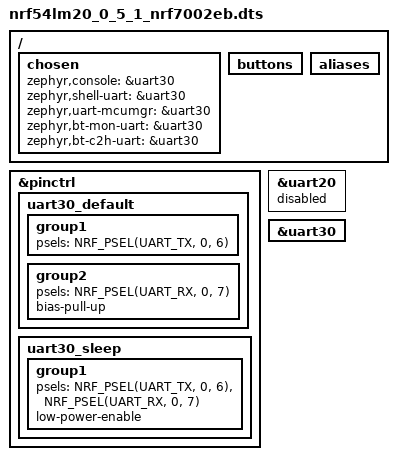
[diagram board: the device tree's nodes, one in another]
/*
 * nRF7002 EB-II SoC overlay for nRF54LM20 revision 0.5.1.
 * SPI and GPIOs come from root overlay via nordic_expansion_spi and
 * nordic_expansion_header.
 */

/* UART20 conflicts with EB-II shield on 0.5.1 board revision; use UART30 */
/ {
	chosen {
		zephyr,console = &uart30;
		zephyr,shell-uart = &uart30;
		zephyr,uart-mcumgr = &uart30;
		zephyr,bt-mon-uart = &uart30;
		zephyr,bt-c2h-uart = &uart30;
	};

	buttons {
		/delete-node/ button_3;
	};

	aliases {
		/delete-property/ sw3;
	};
};

&pinctrl {
	uart30_default: uart30_default {
		group1 {
			psels = <NRF_PSEL(UART_TX, 0, 6)>;
		};

		group2 {
			psels = <NRF_PSEL(UART_RX, 0, 7)>;
			bias-pull-up;
		};
	};

	uart30_sleep: uart30_sleep {
		group1 {
			psels = <NRF_PSEL(UART_TX, 0, 6)>,
				<NRF_PSEL(UART_RX, 0, 7)>;
			low-power-enable;
		};
	};
};

&uart20 {
	status = "disabled";
};

&uart30 {
	status = "okay";
};
